# M451_v1 register map
File version: 1.0
Registers are 32-bit, read-write, reset 0x0 unless marked. A register's access mark holds for its fields unless they carry their own. Offsets are from the block's base; [hi:lo] are bit positions; {n}, {i} and the like mark numbered series; 'fields as' and 'values as' point back to an identical list.

## EBI — EBI Register Map
Base 0x40010000
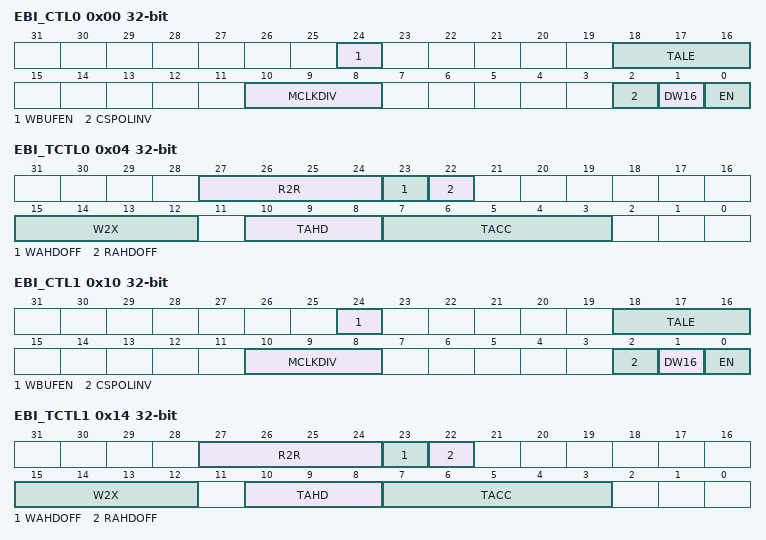
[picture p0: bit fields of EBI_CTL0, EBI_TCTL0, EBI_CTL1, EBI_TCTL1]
0x00 EBI_CTL0 — External Bus Interface Bank0 Control Register
  [24] WBUFEN — EBI Write Buffer Enable Bit. Note: This bit only available in EBI_CTL0 register
    0=EBI write buffer Disabled; 1=EBI write buffer Enabled
  [18:16] TALE — Extend Time of ALE. The EBI_ALE high pulse period (tALE) to latch the address can be controlled by TALE. Note: This field only available in EBI_CTL0 register
  [10:8] MCLKDIV — External Output Clock Divider. The frequency of EBI output clock (MCLK) is controlled by MCLKDIV as follow:
    0=HCLK/1; 1=HCLK/2; 2=HCLK/4; 3=HCLK/8; 4=HCLK/16; 5=HCLK/32
  [2] CSPOLINV — Chip Select Pin Polar Inverse. This bit defines the active level of EBI chip select pin (EBI_nCS).
    0=Chip select pin (EBI_nCS) is active low; 1=Chip select pin (EBI_nCS) is active high
  [1] DW16 — EBI Data Width 16-bit Select. This bit defines if the EBI data width is 8-bit or 16-bit.
    0=EBI data width is 8-bit; 1=EBI data width is 16-bit
  [0] EN — EBI Enable Bit. This bit is the functional enable bit for EBI.
    0=EBI function Disabled; 1=EBI function Enabled
0x04 EBI_TCTL0 — External Bus Interface Bank0 Timing Control Register
  [27:24] R2R — Idle Cycle Between Read-to-read. This field defines the number of R2R idle cycle. When read action is finish and next action is going to read, R2R idle cycle is inserted and EBI_nCS return to idle state.
  [23] WAHDOFF — Access Hold Time Disable Control When Write
    0=The Data Access Hold Time (tAHD) during EBI writing is Enabled; 1=The Data Access Hold Time (tAHD) during EBI writing is Disabled
  [22] RAHDOFF — Access Hold Time Disable Control When Read
    0=The Data Access Hold Time (tAHD) during EBI reading is Enabled; 1=The Data Access Hold Time (tAHD) during EBI reading is Disabled
  [15:12] W2X — Idle Cycle After Write. This field defines the number of W2X idle cycle. When write action is finish, W2X idle cycle is inserted and EBI_nCS return to idle state.
  [10:8] TAHD — EBI Data Access Hold Time. TAHD define data access hold time (tAHD).
  [7:3] TACC — EBI Data Access Time. TACC define data access time (tACC).
0x10 EBI_CTL1 — External Bus Interface Bank1 Control Register
  fields as EBI_CTL0
0x14 EBI_TCTL1 — External Bus Interface Bank1 Timing Control Register
  fields as EBI_TCTL0

## CURSCAT — PDMA Register Map
Base 0x400080C0
{0x0+4i} PDMA_CURSCAT{i} ro reset not defined (i=0..11) — Current Scatter-gather Descriptor Table Address of PDMA Channel n (M45xD/M45xC Only Support Channel 0~7)
  [31:0] CURADDR — PDMA Current Description Address Register (Read Only). This field indicates a 32-bit current external description address of PDMA controller. Note: This field is read only and only used for Scatter-Gather mode to indicate the current external description address.

## DSCT_CTL — PDMA Register Map
Base 0x40008000
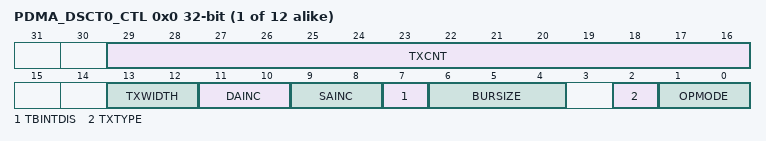
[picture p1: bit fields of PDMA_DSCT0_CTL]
{0x0+0x10*i} PDMA_DSCT{i}_CTL reset not defined (i=0..11) — Descriptor Table Control Register of PDMA Channel n (M45xD/M45xC Only Support Channel 0~7)
  [29:16] TXCNT — Transfer Count. The TXCNT represents the required number of PDMA transfer, the real transfer count is (TXCNT + 1); The maximum transfer count is 16384 , every transfer may be byte, half-word or word that is dependent on TXWIDTH field. Note: When PDMA finish each transfer data, this field will be decrease immediately.
  [13:12] TXWIDTH — Transfer Width Selection. This field is used for transfer width. Note: The PDMA transfer source address (PDMA_DSCT_SA) and PDMA transfer destination address (PDMA_DSCT_DA) should be alignment under the TXWIDTH selection
    0=One byte (8 bit) is transferred for every operation; 1=One half-word (16 bit) is transferred for every operation; 2=One word (32-bit) is transferred for every operation
  [11:10] DAINC — Destination Address Increment. This field is used to set the destination address increment size.
    3=No increment (fixed address)
  [9:8] SAINC — Source Address Increment. This field is used to set the source address increment size.
    3=No increment (fixed address)
  [7] TBINTDIS — Table Interrupt Disable Bit. This field can be used to decide whether to enable table interrupt or not. If the TBINTDIS bit is enabled when PDMA controller finishes transfer task, it will not generates interrupt. Note: If this bit set to '1', the TEMPTYF will not be set.
    0=Table interrupt Enabled; 1=Table interrupt Disabled
  [6:4] BURSIZE — Burst Size. This field is used for peripheral to determine the burst size or used for determine the re-arbitration size. Note: This field is only useful in burst transfer type.
    0=128 Transfers; 1=64 Transfers; 2=32 Transfers; 3=16 Transfers; 4=8 Transfers; 5=4 Transfers; 6=2 Transfers; 7=1 Transfers
  [2] TXTYPE — Transfer Type
    0=Burst transfer type; 1=Single transfer type
  [1:0] OPMODE — PDMA Operation Mode Selection. Note: Before filling transfer task in the Descriptor Table, user must check if the descriptor table is complete.
    0=Idle state: Channel is stopped or this table is complete, when PDMA finish channel table task, OPMODE will be cleared to idle state automatically; 1=Basic mode: The descriptor table only has one task. When this task is finished, the PDMA_INTSTS[n] will be asserted; 2=Scatter-Gather mode: When operating in this mode, user must give the next descriptor table address in PDMA_DSCT_NEXT register; PDMA controller will ignore this task, then load the next task to execute
